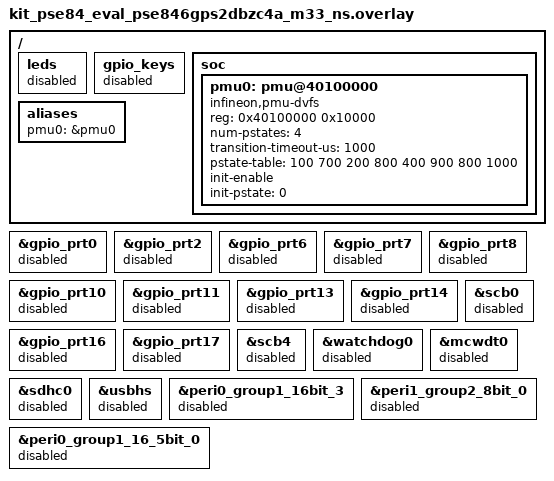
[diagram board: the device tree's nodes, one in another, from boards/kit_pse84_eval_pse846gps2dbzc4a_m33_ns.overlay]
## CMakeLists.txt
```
cmake_minimum_required(VERSION 3.20.0)

set(ZEPHYR_EXTRA_MODULES "${CMAKE_CURRENT_SOURCE_DIR}/../../modules/pmu")

list(APPEND SNIPPET_ROOT ${CMAKE_CURRENT_SOURCE_DIR})
find_package(Zephyr REQUIRED HINTS $ENV{ZEPHYR_BASE})
project(cm33ns_vp_pmu_demo)

target_sources(app PRIVATE src/main.c)
```

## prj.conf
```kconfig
CONFIG_BUILD_OUTPUT_HEX=y

# PMU / DVFS driver
CONFIG_PMU_DVFS=y

# Logging
CONFIG_LOG=y
CONFIG_LOG_DEFAULT_LEVEL=3

# No TFM
CONFIG_BUILD_WITH_TFM=n
```

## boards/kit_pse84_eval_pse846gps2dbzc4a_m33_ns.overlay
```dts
/*
 * Minimal DTS overlay: keep only what is required to boot and print
 * "Hello World" on the console UART (uart2 / scb2).
 *
 * Kept enabled from the board files:
 *   - scb2 (uart2)              -> zephyr,console / zephyr,shell-uart
 *   - peri0_group1_16bit_1      -> uart2 clock divider
 *   - flash_controller / rram0  -> code / storage (required for boot)
 *   - system clocks             -> untouched (SoC default)
 *
 * Everything else that the board enables at boot is turned off here.
 */

/ {
	/* Disable LED / button containers so they do not pull in GPIO ports.
	 * The nodes are kept (not deleted) so that aliases referencing their
	 * child labels (led0..led2, sw0) remain valid.
	 */
	leds      { status = "disabled"; };
	gpio_keys { status = "disabled"; };
};

/* --- GPIO ports (none needed for bare UART console) --------------------- */
&gpio_prt0  { status = "disabled"; };
&gpio_prt2  { status = "disabled"; };
&gpio_prt6  { status = "disabled"; };
&gpio_prt7  { status = "disabled"; };
&gpio_prt8  { status = "disabled"; };
&gpio_prt10 { status = "disabled"; };
&gpio_prt11 { status = "disabled"; };
&gpio_prt13 { status = "disabled"; };
&gpio_prt14 { status = "disabled"; };
&gpio_prt16 { status = "disabled"; };
&gpio_prt17 { status = "disabled"; };

/* --- SCBs / serial we do not use --------------------------------------- */
&scb0 { status = "disabled"; };   /* i2c0 + bmi270 */
&scb4 { status = "disabled"; };   /* uart4 / bt_hci_uart / cyw55513 */

/* --- Timers / watchdog ------------------------------------------------- */
&watchdog0 { status = "disabled"; };
&mcwdt0    { status = "disabled"; };

/* --- Storage / connectivity ------------------------------------------- */
&sdhc0  { status = "disabled"; };  /* SDIO + airoc-wifi */
&usbhs  { status = "disabled"; };

/* --- Peripheral clock dividers only used by disabled peripherals ------ */
&peri0_group1_16bit_3   { status = "disabled"; };  /* i2c0  */
&peri0_group1_16_5bit_0 { status = "disabled"; };  /* uart4 */
&peri1_group2_8bit_0    { status = "disabled"; };  /* sdhc0 */

/* --- Virtual-platform PMU (SystemC/TLM model) --------------------------
 * Generic Power Modeling Unit hooked to the M33-NS bus in the SystemC
 * model. Base address is chosen inside the free peripheral window
 * 0x40000000 .. 0x48000000; the model accepts any base in that range.
 */
/ {
	soc {
		pmu0: pmu@40100000 {
			compatible = "infineon,pmu-dvfs";
			reg = <0x40100000 0x10000>;
			status = "okay";

			num-pstates = <4>;
			transition-timeout-us = <1000>;

			/* (freq-MHz, voltage-mV) pairs, one per P-state.
			 * Ordered low-power (P0) to high-performance (P3).
			 */
			pstate-table = <
				100   700
				200   800
				400   900
				800  1000
			>;

			init-enable;
			init-pstate = <0>;
		};
	};

	aliases {
		pmu0 = &pmu0;
	};
};
```

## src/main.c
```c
/*
 * PMU / DVFS demo
 *
 * SPDX-License-Identifier: Apache-2.0
 *
 * Walks the P-state table programmed from devicetree (P0 -> P3 -> P0),
 * printing the resulting voltage / frequency reported by the PMU model
 * after each transition. Also shows a fault-injection path: a request
 * for an out-of-range P-state which the model reports via
 * DVFSSTATUS.ERROR.
 */
#include <stdio.h>
#include <zephyr/device.h>
#include <zephyr/kernel.h>
#include <zephyr/logging/log.h>

#include "pmu.h"

LOG_MODULE_REGISTER(main, LOG_LEVEL_INF);

#define PMU_NODE DT_ALIAS(pmu0)

static const char *phase_str(uint8_t phase)
{
	switch (phase) {
	case PMU_PHASE_IDLE:
		return "IDLE";
	case PMU_PHASE_VOLT_UP:
		return "VOLT_UP";
	case PMU_PHASE_FREQ_UP:
		return "FREQ_UP";
	case PMU_PHASE_VOLT_DOWN:
		return "VOLT_DOWN";
	case PMU_PHASE_FREQ_DOWN:
		return "FREQ_DOWN";
	default:
		return "?";
	}
}

static void dump_state(const struct device *pmu, const char *tag)
{
	struct pmu_status st;
	uint32_t mv = 0, mhz = 0;

	pmu_get_status(pmu, &st);
	pmu_get_voltage_mv(pmu, &mv);
	pmu_get_freq_mhz(pmu, &mhz);

	printf("[%s] P=%u  V=%u mV  F=%u MHz  busy=%d  pend=%d  phase=%s  "
	       "err=%d\n",
	       tag, st.curr_pstate, mv, mhz, st.busy, st.trans_pending,
	       phase_str(st.trans_phase), st.error);
}

static int switch_pstate(const struct device *pmu, uint8_t target)
{
	int ret;

	printf("--> Requesting P%u\n", target);

	ret = pmu_request_pstate(pmu, target);
	if (ret < 0) {
		printf("    request_pstate failed: %d\n", ret);
		return ret;
	}

	ret = pmu_wait_idle(pmu, K_MSEC(100));
	if (ret < 0) {
		printf("    wait_idle failed: %d\n", ret);
	}

	dump_state(pmu, "after");
	return ret;
}

int main(void)
{
	const struct device *pmu = DEVICE_DT_GET(PMU_NODE);

	printf("PMU DVFS demo (%s)\n", CONFIG_BOARD);

	if (!device_is_ready(pmu)) {
		printf("PMU device not ready\n");
		return -ENODEV;
	}

	/* Show the P-state table that was preloaded from devicetree. */
	printf("Programmed P-state table:\n");
	for (uint8_t i = 0; i < 4; i++) {
		struct pmu_pstate e;

		if (pmu_get_pstate_entry(pmu, i, &e) == 0) {
			printf("  P%u: %u MHz / %u mV\n", i, e.freq_mhz,
			       e.voltage_mv);
		}
	}

	dump_state(pmu, "boot");

	/* Ramp up: P0 -> P1 -> P2 -> P3. */
	for (uint8_t i = 1; i <= 3; i++) {
		switch_pstate(pmu, i);
		k_msleep(200);
	}

	/* Ramp back down to the lowest power state. */
	for (int i = 2; i >= 0; i--) {
		switch_pstate(pmu, (uint8_t)i);
		k_msleep(200);
	}

	/* Fault injection: ask for a P-state above NUMSTATES. The PMU
	 * model must flag ERROR in DVFSSTATUS.
	 */
	printf("\n--> Injecting invalid P-state request (P9)\n");
	pmu_request_pstate(pmu, 9);
	pmu_wait_idle(pmu, K_MSEC(50));
	dump_state(pmu, "err");

	pmu_clear_error(pmu);
	dump_state(pmu, "cleared");

	/* Return to P0 and idle. */
	switch_pstate(pmu, 0);

	printf("Demo done.\n");
	return 0;
}
```
